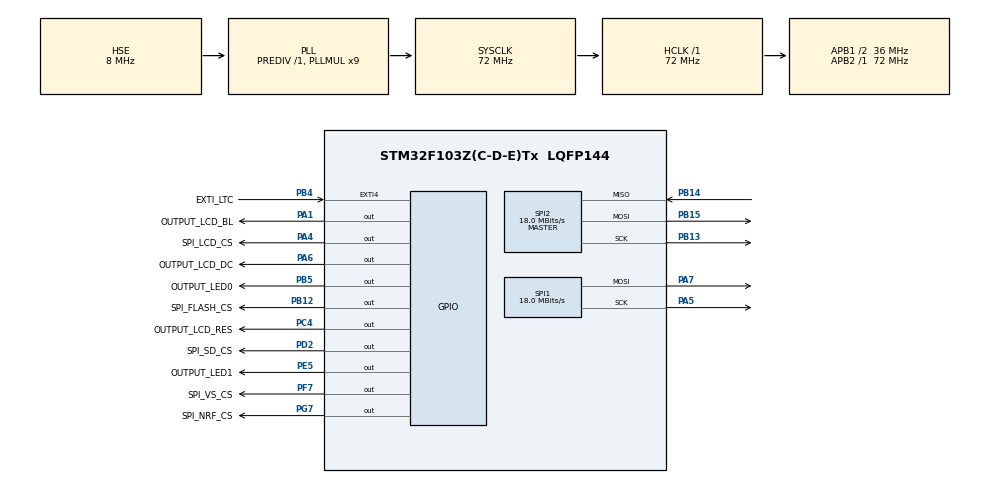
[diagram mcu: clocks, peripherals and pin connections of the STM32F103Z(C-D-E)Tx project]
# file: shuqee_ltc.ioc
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Mcu.Family=STM32F1
Mcu.Name=STM32F103Z(C-D-E)Tx
Mcu.Package=LQFP144
NVIC.EXTI4_IRQn=true\:0\:0\:true\:false\:true
NVIC.PriorityGroup=NVIC_PRIORITYGROUP_4
NVIC.TIM2_IRQn=true\:1\:0\:true\:false\:true
OSC_IN.Mode=HSE-External-Oscillator
OSC_IN.Signal=RCC_OSC_IN
OSC_OUT.Mode=HSE-External-Oscillator
OSC_OUT.Signal=RCC_OSC_OUT
PA1.GPIO_Label=OUTPUT_LCD_BL
PA1.GPIO_Speed=GPIO_SPEED_FREQ_HIGH
PA1.PinState=GPIO_PIN_SET
PA1.Signal=GPIO_Output
PA13.Mode=Serial_Wire
PA13.Signal=SYS_JTMS-SWDIO
PA14.Mode=Serial_Wire
PA14.Signal=SYS_JTCK-SWCLK
PA4.GPIO_Label=SPI_LCD_CS
PA4.GPIO_Speed=GPIO_SPEED_FREQ_HIGH
PA4.PinState=GPIO_PIN_SET
PA4.Signal=GPIO_Output
PA5.Mode=TX_Only_Simplex_Unidirect_Master
PA5.Signal=SPI1_SCK
PA6.GPIO_Label=OUTPUT_LCD_DC
PA6.GPIO_Speed=GPIO_SPEED_FREQ_HIGH
PA6.PinState=GPIO_PIN_SET
PA6.Signal=GPIO_Output
PA7.Mode=TX_Only_Simplex_Unidirect_Master
PA7.Signal=SPI1_MOSI
PB12.GPIO_Label=SPI_FLASH_CS
PB12.GPIO_Speed=GPIO_SPEED_FREQ_HIGH
PB12.PinState=GPIO_PIN_SET
PB12.Signal=GPIO_Output
PB13.Mode=Full_Duplex_Master
PB13.Signal=SPI2_SCK
PB14.Mode=Full_Duplex_Master
PB14.Signal=SPI2_MISO
PB15.Mode=Full_Duplex_Master
PB15.Signal=SPI2_MOSI
PB4.GPIO_Label=EXTI_LTC
PB4.GPIO_ModeDefaultEXTI=GPIO_MODE_IT_RISING_FALLING
PB4.GPIO_PuPd=GPIO_NOPULL
PB4.Signal=GPXTI4
PB5.GPIO_Label=OUTPUT_LED0
PB5.GPIO_Speed=GPIO_SPEED_FREQ_HIGH
PB5.PinState=GPIO_PIN_RESET
PB5.Signal=GPIO_Output
PC14-OSC32_IN.Mode=LSE-External-Oscillator
PC14-OSC32_IN.Signal=RCC_OSC32_IN
PC15-OSC32_OUT.Mode=LSE-External-Oscillator
PC15-OSC32_OUT.Signal=RCC_OSC32_OUT
PC4.GPIO_Label=OUTPUT_LCD_RES
PC4.GPIO_Speed=GPIO_SPEED_FREQ_HIGH
PC4.Signal=GPIO_Output
PD2.GPIO_Label=SPI_SD_CS
PD2.GPIO_Speed=GPIO_SPEED_FREQ_HIGH
PD2.PinState=GPIO_PIN_SET
PD2.Signal=GPIO_Output
PE5.GPIO_Label=OUTPUT_LED1
PE5.GPIO_Speed=GPIO_SPEED_FREQ_HIGH
PE5.Signal=GPIO_Output
PF7.GPIO_Label=SPI_VS_CS
PF7.GPIO_Speed=GPIO_SPEED_FREQ_HIGH
PF7.PinState=GPIO_PIN_SET
PF7.Signal=GPIO_Output
PG7.GPIO_Label=SPI_NRF_CS
PG7.GPIO_Speed=GPIO_SPEED_FREQ_HIGH
PG7.PinState=GPIO_PIN_SET
PG7.Signal=GPIO_Output
ProjectManager.HeapSize=0x200
ProjectManager.StackSize=0x400
ProjectManager.TargetToolchain=MDK-ARM V5
RCC.AHBFreq_Value=72000000
RCC.APB1CLKDivider=RCC_HCLK_DIV2
RCC.APB1Freq_Value=36000000
RCC.APB1TimFreq_Value=72000000
RCC.APB2Freq_Value=72000000
RCC.APB2TimFreq_Value=72000000
RCC.HCLKFreq_Value=72000000
RCC.PLLMUL=RCC_PLL_MUL9
RCC.PLLSourceVirtual=RCC_PLLSOURCE_HSE
RCC.SYSCLKFreq_VALUE=72000000
RCC.SYSCLKSource=RCC_SYSCLKSOURCE_PLLCLK
RCC.USBFreq_Value=72000000
SPI1.BaudRatePrescaler=SPI_BAUDRATEPRESCALER_4
SPI1.CalculateBaudRate=18.0 MBits/s
SPI1.Direction=SPI_DIRECTION_2LINES
SPI1.Mode=SPI_MODE_MASTER
SPI1.VirtualType=VM_MASTER
SPI2.BaudRatePrescaler=SPI_BAUDRATEPRESCALER_2
SPI2.CLKPhase=SPI_PHASE_2EDGE
SPI2.CLKPolarity=SPI_POLARITY_HIGH
SPI2.CRCCalculation=SPI_CRCCALCULATION_ENABLE
SPI2.CalculateBaudRate=18.0 MBits/s
SPI2.Direction=SPI_DIRECTION_2LINES
SPI2.Mode=SPI_MODE_MASTER
SPI2.VirtualType=VM_MASTER
TIM2.Period=259
TIM2.Prescaler=71
TIM3.Period=50000
TIM3.Prescaler=71
TIM4.Prescaler=71
VP_TIM2_VS_ClockSourceINT.Mode=Internal
VP_TIM3_VS_ClockSourceINT.Mode=Internal
VP_TIM4_VS_ClockSourceINT.Mode=Internal
board=shuqee_ltc

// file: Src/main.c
/**
  ******************************************************************************
  * File Name          : main.c
  * Description        : Main program body
  ******************************************************************************
  ** This notice applies to any and all portions of this file
  * that are not between comment pairs USER CODE BEGIN and
  * USER CODE END. Other portions of this file, whether
  * inserted by the user or by software development tools
  * are owned by their respective copyright owners.
  *
  * COPYRIGHT(c) 2017 STMicroelectronics
  *
  * Redistribution and use in source and binary forms, with or without modification,
  * are permitted provided that the following conditions are met:
  *   1. Redistributions of source code must retain the above copyright notice,
  *      this list of conditions and the following disclaimer.
  *   2. Redistributions in binary form must reproduce the above copyright notice,
  *      this list of conditions and the following disclaimer in the documentation
  *      and/or other materials provided with the distribution.
  *   3. Neither the name of STMicroelectronics nor the names of its contributors
  *      may be used to endorse or promote products derived from this software
  *      without specific prior written permission.
  *
  * THIS SOFTWARE IS PROVIDED BY THE COPYRIGHT HOLDERS AND CONTRIBUTORS "AS IS"
  * AND ANY EXPRESS OR IMPLIED WARRANTIES, INCLUDING, BUT NOT LIMITED TO, THE
  * IMPLIED WARRANTIES OF MERCHANTABILITY AND FITNESS FOR A PARTICULAR PURPOSE ARE
  * DISCLAIMED. IN NO EVENT SHALL THE COPYRIGHT HOLDER OR CONTRIBUTORS BE LIABLE
  * FOR ANY DIRECT, INDIRECT, INCIDENTAL, SPECIAL, EXEMPLARY, OR CONSEQUENTIAL
  * DAMAGES (INCLUDING, BUT NOT LIMITED TO, PROCUREMENT OF SUBSTITUTE GOODS OR
  * SERVICES; LOSS OF USE, DATA, OR PROFITS; OR BUSINESS INTERRUPTION) HOWEVER
  * CAUSED AND ON ANY THEORY OF LIABILITY, WHETHER IN CONTRACT, STRICT LIABILITY,
  * OR TORT (INCLUDING NEGLIGENCE OR OTHERWISE) ARISING IN ANY WAY OUT OF THE USE
  * OF THIS SOFTWARE, EVEN IF ADVISED OF THE POSSIBILITY OF SUCH DAMAGE.
  *
  ******************************************************************************
  */
#include "main.h"
#include "stm32f1xx_hal.h"

/* USER CODE BEGIN Includes */
#include "user_config.h"
#include "user_io.h"
#include "user_time.h"
#include "user_spi.h"
#include "spi_flash.h"
#include "spi_lcd.h"
/* USER CODE END Includes */

SPI_HandleTypeDef hspi1;
SPI_HandleTypeDef hspi2;

TIM_HandleTypeDef htim2;
TIM_HandleTypeDef htim3;
TIM_HandleTypeDef htim4;

/* USER CODE BEGIN PV */
/* Private variables ---------------------------------------------------------*/

/* USER CODE END PV */

void SystemClock_Config(void);
static void MX_GPIO_Init(void);
static void MX_TIM2_Init(void);
static void MX_TIM3_Init(void);
static void MX_SPI2_Init(void);
static void MX_TIM4_Init(void);
static void MX_SPI1_Init(void);

/* USER CODE BEGIN PFP */
/* Private function prototypes -----------------------------------------------*/

/* USER CODE END PFP */

int main(void)
{

  /* MCU Configuration----------------------------------------------------------*/

  /* Reset of all peripherals, Initializes the Flash interface and the Systick. */
  HAL_Init();

  /* Configure the system clock */
  SystemClock_Config();

  /* Initialize all configured peripherals */
  MX_GPIO_Init();
  MX_TIM2_Init();
  MX_TIM3_Init();
  MX_SPI2_Init();
  MX_TIM4_Init();
  MX_SPI1_Init();

  /* USER CODE BEGIN 2 */
	user_io_init();
	user_spi_init();
	spi_flash_init();
	user_time_init();
	spi_lcd_init();
  /* USER CODE END 2 */

  /* Infinite loop */
  while (1)
  {

  /* USER CODE BEGIN 3 */
	lcd_test();
  }
  /* USER CODE END 3 */

}

/** System Clock Configuration
*/
void SystemClock_Config(void)
{

  RCC_OscInitTypeDef RCC_OscInitStruct;
  RCC_ClkInitTypeDef RCC_ClkInitStruct;

    /**Initializes the CPU, AHB and APB busses clocks
    */
  RCC_OscInitStruct.OscillatorType = RCC_OSCILLATORTYPE_HSE;
  RCC_OscInitStruct.HSEState = RCC_HSE_ON;
  RCC_OscInitStruct.HSEPredivValue = RCC_HSE_PREDIV_DIV1;
  RCC_OscInitStruct.HSIState = RCC_HSI_ON;
  RCC_OscInitStruct.PLL.PLLState = RCC_PLL_ON;
  RCC_OscInitStruct.PLL.PLLSource = RCC_PLLSOURCE_HSE;
  RCC_OscInitStruct.PLL.PLLMUL = RCC_PLL_MUL9;
  if (HAL_RCC_OscConfig(&RCC_OscInitStruct) != HAL_OK)
  {
    _Error_Handler(__FILE__, __LINE__);
  }

    /**Initializes the CPU, AHB and APB busses clocks
    */
  RCC_ClkInitStruct.ClockType = RCC_CLOCKTYPE_HCLK|RCC_CLOCKTYPE_SYSCLK
                              |RCC_CLOCKTYPE_PCLK1|RCC_CLOCKTYPE_PCLK2;
  RCC_ClkInitStruct.SYSCLKSource = RCC_SYSCLKSOURCE_PLLCLK;
  RCC_ClkInitStruct.AHBCLKDivider = RCC_SYSCLK_DIV1;
  RCC_ClkInitStruct.APB1CLKDivider = RCC_HCLK_DIV2;
  RCC_ClkInitStruct.APB2CLKDivider = RCC_HCLK_DIV1;

  if (HAL_RCC_ClockConfig(&RCC_ClkInitStruct, FLASH_LATENCY_2) != HAL_OK)
  {
    _Error_Handler(__FILE__, __LINE__);
  }

    /**Configure the Systick interrupt time
    */
  HAL_SYSTICK_Config(HAL_RCC_GetHCLKFreq()/1000);

    /**Configure the Systick
    */
  HAL_SYSTICK_CLKSourceConfig(SYSTICK_CLKSOURCE_HCLK);

  /* SysTick_IRQn interrupt configuration */
  HAL_NVIC_SetPriority(SysTick_IRQn, 0, 0);
}

/* SPI1 init function */
static void MX_SPI1_Init(void)
{

  hspi1.Instance = SPI1;
  hspi1.Init.Mode = SPI_MODE_MASTER;
  hspi1.Init.Direction = SPI_DIRECTION_2LINES;
  hspi1.Init.DataSize = SPI_DATASIZE_8BIT;
  hspi1.Init.CLKPolarity = SPI_POLARITY_LOW;
  hspi1.Init.CLKPhase = SPI_PHASE_1EDGE;
  hspi1.Init.NSS = SPI_NSS_SOFT;
  hspi1.Init.BaudRatePrescaler = SPI_BAUDRATEPRESCALER_4;
  hspi1.Init.FirstBit = SPI_FIRSTBIT_MSB;
  hspi1.Init.TIMode = SPI_TIMODE_DISABLE;
  hspi1.Init.CRCCalculation = SPI_CRCCALCULATION_DISABLE;
  hspi1.Init.CRCPolynomial = 10;
  if (HAL_SPI_Init(&hspi1) != HAL_OK)
  {
    _Error_Handler(__FILE__, __LINE__);
  }

}

/* SPI2 init function */
static void MX_SPI2_Init(void)
{

  hspi2.Instance = SPI2;
  hspi2.Init.Mode = SPI_MODE_MASTER;
  hspi2.Init.Direction = SPI_DIRECTION_2LINES;
  hspi2.Init.DataSize = SPI_DATASIZE_8BIT;
  hspi2.Init.CLKPolarity = SPI_POLARITY_HIGH;
  hspi2.Init.CLKPhase = SPI_PHASE_2EDGE;
  hspi2.Init.NSS = SPI_NSS_SOFT;
  hspi2.Init.BaudRatePrescaler = SPI_BAUDRATEPRESCALER_2;
  hspi2.Init.FirstBit = SPI_FIRSTBIT_MSB;
  hspi2.Init.TIMode = SPI_TIMODE_DISABLE;
  hspi2.Init.CRCCalculation = SPI_CRCCALCULATION_ENABLE;
  hspi2.Init.CRCPolynomial = 10;
  if (HAL_SPI_Init(&hspi2) != HAL_OK)
  {
    _Error_Handler(__FILE__, __LINE__);
  }

}

/* TIM2 init function */
static void MX_TIM2_Init(void)
{

  TIM_ClockConfigTypeDef sClockSourceConfig;
  TIM_MasterConfigTypeDef sMasterConfig;

  htim2.Instance = TIM2;
  htim2.Init.Prescaler = 71;
  htim2.Init.CounterMode = TIM_COUNTERMODE_UP;
  htim2.Init.Period = 259;
  htim2.Init.ClockDivision = TIM_CLOCKDIVISION_DIV1;
  htim2.Init.AutoReloadPreload = TIM_AUTORELOAD_PRELOAD_DISABLE;
  if (HAL_TIM_Base_Init(&htim2) != HAL_OK)
  {
    _Error_Handler(__FILE__, __LINE__);
  }

  sClockSourceConfig.ClockSource = TIM_CLOCKSOURCE_INTERNAL;
  if (HAL_TIM_ConfigClockSource(&htim2, &sClockSourceConfig) != HAL_OK)
  {
    _Error_Handler(__FILE__, __LINE__);
  }

  sMasterConfig.MasterOutputTrigger = TIM_TRGO_RESET;
  sMasterConfig.MasterSlaveMode = TIM_MASTERSLAVEMODE_DISABLE;
  if (HAL_TIMEx_MasterConfigSynchronization(&htim2, &sMasterConfig) != HAL_OK)
  {
    _Error_Handler(__FILE__, __LINE__);
  }

}

/* TIM3 init function */
static void MX_TIM3_Init(void)
{

  TIM_ClockConfigTypeDef sClockSourceConfig;
  TIM_MasterConfigTypeDef sMasterConfig;

  htim3.Instance = TIM3;
  htim3.Init.Prescaler = 71;
  htim3.Init.CounterMode = TIM_COUNTERMODE_UP;
  htim3.Init.Period = 50000;
  htim3.Init.ClockDivision = TIM_CLOCKDIVISION_DIV1;
  htim3.Init.AutoReloadPreload = TIM_AUTORELOAD_PRELOAD_DISABLE;
  if (HAL_TIM_Base_Init(&htim3) != HAL_OK)
  {
    _Error_Handler(__FILE__, __LINE__);
  }

  sClockSourceConfig.ClockSource = TIM_CLOCKSOURCE_INTERNAL;
  if (HAL_TIM_ConfigClockSource(&htim3, &sClockSourceConfig) != HAL_OK)
  {
    _Error_Handler(__FILE__, __LINE__);
  }

  sMasterConfig.MasterOutputTrigger = TIM_TRGO_RESET;
  sMasterConfig.MasterSlaveMode = TIM_MASTERSLAVEMODE_DISABLE;
  if (HAL_TIMEx_MasterConfigSynchronization(&htim3, &sMasterConfig) != HAL_OK)
  {
    _Error_Handler(__FILE__, __LINE__);
  }

}

/* TIM4 init function */
static void MX_TIM4_Init(void)
{

  TIM_ClockConfigTypeDef sClockSourceConfig;
  TIM_MasterConfigTypeDef sMasterConfig;

  htim4.Instance = TIM4;
  htim4.Init.Prescaler = 71;
  htim4.Init.CounterMode = TIM_COUNTERMODE_UP;
  htim4.Init.Period = 0;
  htim4.Init.ClockDivision = TIM_CLOCKDIVISION_DIV1;
  htim4.Init.AutoReloadPreload = TIM_AUTORELOAD_PRELOAD_DISABLE;
  if (HAL_TIM_Base_Init(&htim4) != HAL_OK)
  {
    _Error_Handler(__FILE__, __LINE__);
  }

  sClockSourceConfig.ClockSource = TIM_CLOCKSOURCE_INTERNAL;
  if (HAL_TIM_ConfigClockSource(&htim4, &sClockSourceConfig) != HAL_OK)
  {
    _Error_Handler(__FILE__, __LINE__);
  }

  sMasterConfig.MasterOutputTrigger = TIM_TRGO_RESET;
  sMasterConfig.MasterSlaveMode = TIM_MASTERSLAVEMODE_DISABLE;
  if (HAL_TIMEx_MasterConfigSynchronization(&htim4, &sMasterConfig) != HAL_OK)
  {
    _Error_Handler(__FILE__, __LINE__);
  }

}

/** Configure pins as
        * Analog
        * Input
        * Output
        * EVENT_OUT
        * EXTI
*/
static void MX_GPIO_Init(void)
{

  GPIO_InitTypeDef GPIO_InitStruct;

  /* GPIO Ports Clock Enable */
  __HAL_RCC_GPIOE_CLK_ENABLE();
  __HAL_RCC_GPIOC_CLK_ENABLE();
  __HAL_RCC_GPIOF_CLK_ENABLE();
  __HAL_RCC_GPIOA_CLK_ENABLE();
  __HAL_RCC_GPIOB_CLK_ENABLE();
  __HAL_RCC_GPIOG_CLK_ENABLE();
  __HAL_RCC_GPIOD_CLK_ENABLE();

  /*Configure GPIO pin Output Level */
  HAL_GPIO_WritePin(OUTPUT_LED1_GPIO_Port, OUTPUT_LED1_Pin, GPIO_PIN_RESET);

  /*Configure GPIO pin Output Level */
  HAL_GPIO_WritePin(SPI_VS_CS_GPIO_Port, SPI_VS_CS_Pin, GPIO_PIN_SET);

  /*Configure GPIO pin Output Level */
  HAL_GPIO_WritePin(GPIOA, OUTPUT_LCD_BL_Pin|SPI_LCD_CS_Pin|OUTPUT_LCD_DC_Pin, GPIO_PIN_SET);

  /*Configure GPIO pin Output Level */
  HAL_GPIO_WritePin(OUTPUT_LCD_RES_GPIO_Port, OUTPUT_LCD_RES_Pin, GPIO_PIN_RESET);

  /*Configure GPIO pin Output Level */
  HAL_GPIO_WritePin(SPI_FLASH_CS_GPIO_Port, SPI_FLASH_CS_Pin, GPIO_PIN_SET);

  /*Configure GPIO pin Output Level */
  HAL_GPIO_WritePin(SPI_NRF_CS_GPIO_Port, SPI_NRF_CS_Pin, GPIO_PIN_SET);

  /*Configure GPIO pin Output Level */
  HAL_GPIO_WritePin(SPI_SD_CS_GPIO_Port, SPI_SD_CS_Pin, GPIO_PIN_SET);

  /*Configure GPIO pin Output Level */
  HAL_GPIO_WritePin(OUTPUT_LED0_GPIO_Port, OUTPUT_LED0_Pin, GPIO_PIN_RESET);

  /*Configure GPIO pin : OUTPUT_LED1_Pin */
  GPIO_InitStruct.Pin = OUTPUT_LED1_Pin;
  GPIO_InitStruct.Mode = GPIO_MODE_OUTPUT_PP;
  GPIO_InitStruct.Speed = GPIO_SPEED_FREQ_HIGH;
  HAL_GPIO_Init(OUTPUT_LED1_GPIO_Port, &GPIO_InitStruct);

  /*Configure GPIO pin : SPI_VS_CS_Pin */
  GPIO_InitStruct.Pin = SPI_VS_CS_Pin;
  GPIO_InitStruct.Mode = GPIO_MODE_OUTPUT_PP;
  GPIO_InitStruct.Speed = GPIO_SPEED_FREQ_HIGH;
  HAL_GPIO_Init(SPI_VS_CS_GPIO_Port, &GPIO_InitStruct);

  /*Configure GPIO pins : OUTPUT_LCD_BL_Pin SPI_LCD_CS_Pin OUTPUT_LCD_DC_Pin */
  GPIO_InitStruct.Pin = OUTPUT_LCD_BL_Pin|SPI_LCD_CS_Pin|OUTPUT_LCD_DC_Pin;
  GPIO_InitStruct.Mode = GPIO_MODE_OUTPUT_PP;
  GPIO_InitStruct.Speed = GPIO_SPEED_FREQ_HIGH;
  HAL_GPIO_Init(GPIOA, &GPIO_InitStruct);

  /*Configure GPIO pin : OUTPUT_LCD_RES_Pin */
  GPIO_InitStruct.Pin = OUTPUT_LCD_RES_Pin;
  GPIO_InitStruct.Mode = GPIO_MODE_OUTPUT_PP;
  GPIO_InitStruct.Speed = GPIO_SPEED_FREQ_HIGH;
  HAL_GPIO_Init(OUTPUT_LCD_RES_GPIO_Port, &GPIO_InitStruct);

  /*Configure GPIO pins : SPI_FLASH_CS_Pin OUTPUT_LED0_Pin */
  GPIO_InitStruct.Pin = SPI_FLASH_CS_Pin|OUTPUT_LED0_Pin;
  GPIO_InitStruct.Mode = GPIO_MODE_OUTPUT_PP;
  GPIO_InitStruct.Speed = GPIO_SPEED_FREQ_HIGH;
  HAL_GPIO_Init(GPIOB, &GPIO_InitStruct);

  /*Configure GPIO pin : SPI_NRF_CS_Pin */
  GPIO_InitStruct.Pin = SPI_NRF_CS_Pin;
  GPIO_InitStruct.Mode = GPIO_MODE_OUTPUT_PP;
  GPIO_InitStruct.Speed = GPIO_SPEED_FREQ_HIGH;
  HAL_GPIO_Init(SPI_NRF_CS_GPIO_Port, &GPIO_InitStruct);

  /*Configure GPIO pin : SPI_SD_CS_Pin */
  GPIO_InitStruct.Pin = SPI_SD_CS_Pin;
  GPIO_InitStruct.Mode = GPIO_MODE_OUTPUT_PP;
  GPIO_InitStruct.Speed = GPIO_SPEED_FREQ_HIGH;
  HAL_GPIO_Init(SPI_SD_CS_GPIO_Port, &GPIO_InitStruct);

  /*Configure GPIO pin : EXTI_LTC_Pin */
  GPIO_InitStruct.Pin = EXTI_LTC_Pin;
  GPIO_InitStruct.Mode = GPIO_MODE_IT_RISING_FALLING;
  GPIO_InitStruct.Pull = GPIO_NOPULL;
  HAL_GPIO_Init(EXTI_LTC_GPIO_Port, &GPIO_InitStruct);

  /* EXTI interrupt init*/
  HAL_NVIC_SetPriority(EXTI4_IRQn, 0, 0);
  HAL_NVIC_EnableIRQ(EXTI4_IRQn);

}

void _Error_Handler(char * file, int line)
{
  while(1)
  {
  }
}

/************************ (C) COPYRIGHT STMicroelectronics *****END OF FILE****/
